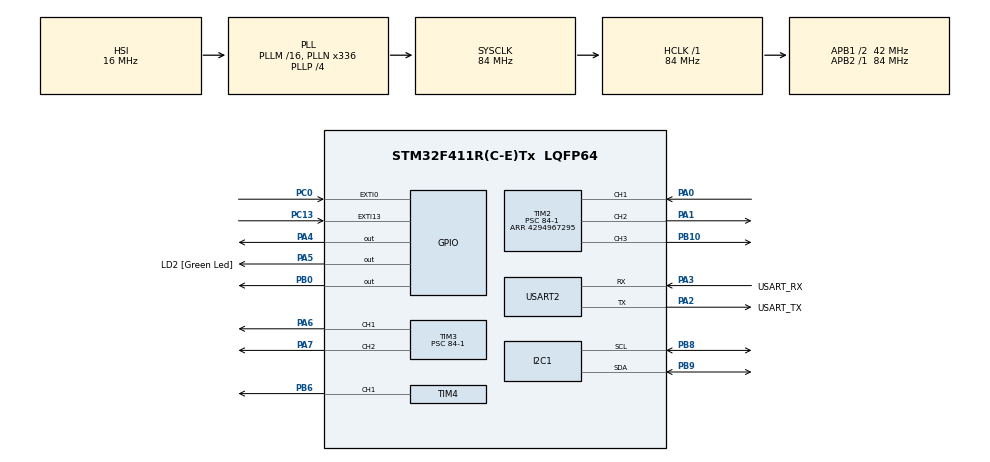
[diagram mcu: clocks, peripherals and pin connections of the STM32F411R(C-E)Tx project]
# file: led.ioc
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ADC1.Channel-0\#ChannelRegularConversion=ADC_CHANNEL_TEMPSENSOR
ADC1.ContinuousConvMode=ENABLE
ADC1.DMAContinuousRequests=ENABLE
ADC1.EOCSelection=ADC_EOC_SINGLE_CONV
ADC1.NbrOfConversion=1
ADC1.NbrOfConversionFlag=1
ADC1.Rank-0\#ChannelRegularConversion=1
ADC1.SamplingTime-0\#ChannelRegularConversion=ADC_SAMPLETIME_480CYCLES
ADC1.ScanConvMode=ENABLE
ADC1.master=1
Dma.ADC1.1.Direction=DMA_PERIPH_TO_MEMORY
Dma.ADC1.1.FIFOMode=DMA_FIFOMODE_DISABLE
Dma.ADC1.1.Instance=DMA2_Stream0
Dma.ADC1.1.MemDataAlignment=DMA_MDATAALIGN_WORD
Dma.ADC1.1.MemInc=DMA_MINC_ENABLE
Dma.ADC1.1.Mode=DMA_CIRCULAR
Dma.ADC1.1.PeriphDataAlignment=DMA_PDATAALIGN_WORD
Dma.ADC1.1.PeriphInc=DMA_PINC_DISABLE
Dma.ADC1.1.Priority=DMA_PRIORITY_LOW
Dma.Request0=USART2_RX
Dma.Request1=ADC1
Dma.USART2_RX.0.Direction=DMA_PERIPH_TO_MEMORY
Dma.USART2_RX.0.FIFOMode=DMA_FIFOMODE_DISABLE
Dma.USART2_RX.0.Instance=DMA1_Stream5
Dma.USART2_RX.0.MemDataAlignment=DMA_MDATAALIGN_BYTE
Dma.USART2_RX.0.MemInc=DMA_MINC_ENABLE
Dma.USART2_RX.0.Mode=DMA_CIRCULAR
Dma.USART2_RX.0.PeriphDataAlignment=DMA_PDATAALIGN_BYTE
Dma.USART2_RX.0.PeriphInc=DMA_PINC_DISABLE
Dma.USART2_RX.0.Priority=DMA_PRIORITY_LOW
FREERTOS.Tasks01=defaultTask,42,128,StartDefaultTask,As weak,NULL,Dynamic,NULL,NULL;myTask_LED,24,128,StartTaskLED,As weak,NULL,Dynamic,NULL,NULL;myTaskCLI,24,1024,StartTaskCLI,As weak,NULL,Dynamic,NULL,NULL;myTaskHCS04,24,128,StartTaskHCS04,As weak,NULL,Dynamic,NULL,NULL;myTaskDHT11,24,128,StartTaskDHT11,As weak,NULL,Dynamic,NULL,NULL;myTask01,41,128,StartTask01,As weak,NULL,Dynamic,NULL,NULL;myTask02,41,128,StartTask02,As weak,NULL,Dynamic,NULL,NULL
FREERTOS.configUSE_NEWLIB_REENTRANT=1
I2C1.I2C_Mode=I2C_Fast
Mcu.Family=STM32F4
Mcu.Name=STM32F411R(C-E)Tx
Mcu.Package=LQFP64
NVIC.ADC_IRQn=true\:5\:0\:false\:false\:true\:true\:true\:true\:true
NVIC.DMA1_Stream5_IRQn=true\:5\:0\:false\:false\:true\:true\:false\:true\:true
NVIC.DMA2_Stream0_IRQn=true\:5\:0\:false\:false\:true\:true\:false\:true\:true
NVIC.EXTI0_IRQn=true\:5\:0\:false\:false\:true\:true\:true\:true\:true
NVIC.EXTI15_10_IRQn=true\:5\:0\:false\:false\:true\:true\:true\:true\:true
NVIC.PriorityGroup=NVIC_PRIORITYGROUP_4
NVIC.RTC_Alarm_IRQn=true\:5\:0\:false\:false\:true\:true\:true\:true\:true
NVIC.TIM1_UP_TIM10_IRQn=true\:15\:0\:false\:false\:true\:false\:false\:true\:true
NVIC.TIM2_IRQn=true\:5\:0\:false\:false\:true\:true\:true\:true\:true
NVIC.TIM3_IRQn=true\:5\:0\:false\:false\:true\:true\:true\:true\:true
NVIC.TimeBase=TIM1_UP_TIM10_IRQn
NVIC.TimeBaseIP=TIM10
NVIC.USART2_IRQn=true\:5\:0\:false\:false\:true\:true\:true\:true\:true
PA0-WKUP.Signal=S_TIM2_CH1_ETR
PA1.Signal=S_TIM2_CH2
PA13.GPIO_Label=TMS
PA13.Mode=Serial_Wire
PA13.Signal=SYS_JTMS-SWDIO
PA14.GPIO_Label=TCK
PA14.Mode=Serial_Wire
PA14.Signal=SYS_JTCK-SWCLK
PA2.GPIO_Label=USART_TX
PA2.Mode=Asynchronous
PA2.Signal=USART2_TX
PA3.GPIO_Label=USART_RX
PA3.Mode=Asynchronous
PA3.Signal=USART2_RX
PA4.Signal=GPIO_Output
PA5.GPIO_Label=LD2 [Green Led]
PA5.Signal=GPIO_Output
PA6.Signal=S_TIM3_CH1
PA7.Signal=S_TIM3_CH2
PB0.Signal=GPIO_Output
PB10.Signal=S_TIM2_CH3
PB3.GPIO_Label=SWO
PB3.Signal=SYS_JTDO-SWO
PB6.Signal=S_TIM4_CH1
PB8.Mode=I2C
PB8.Signal=I2C1_SCL
PB9.Mode=I2C
PB9.Signal=I2C1_SDA
PC0.GPIO_ModeDefaultEXTI=GPIO_MODE_IT_FALLING
PC0.Signal=GPXTI0
PC13-ANTI_TAMP.Signal=GPXTI13
PC14-OSC32_IN.Mode=LSE-External-Oscillator
PC14-OSC32_IN.Signal=RCC_OSC32_IN
PC15-OSC32_OUT.Mode=LSE-External-Oscillator
PC15-OSC32_OUT.Signal=RCC_OSC32_OUT
PH0\ -\ OSC_IN.Mode=HSE-External-Clock-Source
PH0\ -\ OSC_IN.Signal=RCC_OSC_IN
PH1\ -\ OSC_OUT.Mode=HSE-External-Clock-Source
PH1\ -\ OSC_OUT.Signal=RCC_OSC_OUT
ProjectManager.HeapSize=0x200
ProjectManager.StackSize=0x400
ProjectManager.TargetToolchain=CMake
RCC.48MHZClocksFreq_Value=84000000
RCC.AHBFreq_Value=84000000
RCC.APB1CLKDivider=RCC_HCLK_DIV2
RCC.APB1Freq_Value=42000000
RCC.APB1TimFreq_Value=84000000
RCC.APB2Freq_Value=84000000
RCC.APB2TimFreq_Value=84000000
RCC.CortexFreq_Value=84000000
RCC.FLatency-AdvancedSettings=FLASH_LATENCY_2
RCC.HCLKFreq_Value=84000000
RCC.HSE_VALUE=8000000
RCC.HSI_VALUE=16000000
RCC.PLLN=336
RCC.PLLP=RCC_PLLP_DIV4
RCC.SYSCLKFreq_VALUE=84000000
RCC.SYSCLKSource=RCC_SYSCLKSOURCE_PLLCLK
RCC.VCOOutputFreq_Value=336000000
RTC.Alarm=RTC_ALARM_A
RTC.AlarmMaskDateWeekDay=RTC_ALARMMASK_DATEWEEKDAY
RTC.AlarmMaskHours=RTC_ALARMMASK_HOURS
RTC.AlarmMaskMinutes=RTC_ALARMMASK_MINUTES
RTC.Alarm_B=RTC_ALARM_B
RTC.Date=24
RTC.Hours=15
RTC.Minutes=47
RTC.Month=RTC_MONTH_AUGUST
RTC.Seconds_A=10
RTC.Year=26
SH.S_TIM2_CH1_ETR.0=TIM2_CH1,Input_Capture1_from_TI1
SH.S_TIM2_CH2.0=TIM2_CH2,PWM Generation2 CH2
SH.S_TIM2_CH3.0=TIM2_CH3,PWM Generation3 CH3
SH.S_TIM3_CH1.0=TIM3_CH1,PWM Generation1 CH1
SH.S_TIM3_CH2.0=TIM3_CH2,PWM Generation2 CH2
SH.S_TIM4_CH1.0=TIM4_CH1,PWM Generation1 CH1
TIM2.Channel-Input_Capture1_from_TI1=TIM_CHANNEL_1
TIM2.Channel-PWM\ Generation2\ CH2=TIM_CHANNEL_2
TIM2.Channel-PWM\ Generation3\ CH3=TIM_CHANNEL_3
TIM2.ICFilter_CH1=4
TIM2.ICPolarity_CH1=TIM_INPUTCHANNELPOLARITY_FALLING
TIM2.Period=4294967295
TIM2.Prescaler=84-1
TIM2.Pulse-PWM\ Generation2\ CH2=500-1
TIM2.Pulse-PWM\ Generation3\ CH3=500-1
TIM3.Channel-PWM\ Generation1\ CH1=TIM_CHANNEL_1
TIM3.Channel-PWM\ Generation2\ CH2=TIM_CHANNEL_2
TIM3.Period=1000-1
TIM3.Prescaler=84-1
TIM3.Pulse-PWM\ Generation1\ CH1=500-1
TIM3.Pulse-PWM\ Generation2\ CH2=500-1
TIM4.Channel-PWM\ Generation1\ CH1=TIM_CHANNEL_1
TIM4.Period=1000-1
TIM4.Prescaler=84-1
TIM4.Pulse-PWM\ Generation1\ CH1=500-1
USART2.VirtualMode=VM_ASYNC
VP_ADC1_TempSens_Input.Mode=IN-TempSens
VP_FREERTOS_VS_CMSIS_V2.Mode=CMSIS_V2
VP_RTC_VS_RTC_Activate.Mode=RTC_Enabled
VP_RTC_VS_RTC_Alarm_A_Intern.Mode=Alarm A
VP_RTC_VS_RTC_Alarm_B_Intern.Mode=Alarm B
VP_RTC_VS_RTC_Calendar.Mode=RTC_Calendar
VP_SYS_VS_tim10.Mode=TIM10
VP_TIM2_VS_ClockSourceINT.Mode=Internal
VP_TIM3_VS_ClockSourceINT.Mode=Internal
VP_TIM4_VS_ClockSourceINT.Mode=Internal
board=NUCLEO-F411RE

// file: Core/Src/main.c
/* USER CODE BEGIN Header */
/**
  ******************************************************************************
  * @file           : main.c
  * @brief          : Main program body
  ******************************************************************************
  * @attention
  *
  * Copyright (c) 2026 STMicroelectronics.
  * All rights reserved.
  *
  * This software is licensed under terms that can be found in the LICENSE file
  * in the root directory of this software component.
  * If no LICENSE file comes with this software, it is provided AS-IS.
  *
  ******************************************************************************
  */
/* USER CODE END Header */
#include "main.h"
#include "cmsis_os.h"
#include "adc.h"
#include "dma.h"
#include "i2c.h"
#include "rtc.h"
#include "tim.h"
#include "usart.h"
#include "gpio.h"

/* USER CODE BEGIN Includes */
#include "apMain.h"
/* USER CODE END Includes */

void SystemClock_Config(void);
void MX_FREERTOS_Init(void);

int main(void)
{

  /* MCU Configuration--------------------------------------------------------*/

  /* Reset of all peripherals, Initializes the Flash interface and the Systick. */
  HAL_Init();

  /* Configure the system clock */
  SystemClock_Config();

  /* Initialize all configured peripherals */
  MX_GPIO_Init();
  MX_DMA_Init();
  MX_USART2_UART_Init();
  MX_ADC1_Init();
  MX_I2C1_Init();
  MX_TIM2_Init();
  MX_TIM3_Init();
  MX_RTC_Init();
  MX_TIM4_Init();

  /* Init scheduler */
  osKernelInitialize();  /* Call init function for freertos objects (in cmsis_os2.c) */
  MX_FREERTOS_Init();

  /* Start scheduler */
  osKernelStart();

  /* We should never get here as control is now taken by the scheduler */

  /* Infinite loop */
  while (1)
  {

  }
}

void SystemClock_Config(void)
{
  RCC_OscInitTypeDef RCC_OscInitStruct = {0};
  RCC_ClkInitTypeDef RCC_ClkInitStruct = {0};

  /** Configure the main internal regulator output voltage
  */
  __HAL_RCC_PWR_CLK_ENABLE();
  __HAL_PWR_VOLTAGESCALING_CONFIG(PWR_REGULATOR_VOLTAGE_SCALE1);

  /** Initializes the RCC Oscillators according to the specified parameters
  * in the RCC_OscInitTypeDef structure.
  */
  RCC_OscInitStruct.OscillatorType = RCC_OSCILLATORTYPE_HSI|RCC_OSCILLATORTYPE_LSI;
  RCC_OscInitStruct.HSIState = RCC_HSI_ON;
  RCC_OscInitStruct.HSICalibrationValue = RCC_HSICALIBRATION_DEFAULT;
  RCC_OscInitStruct.LSIState = RCC_LSI_ON;
  RCC_OscInitStruct.PLL.PLLState = RCC_PLL_ON;
  RCC_OscInitStruct.PLL.PLLSource = RCC_PLLSOURCE_HSI;
  RCC_OscInitStruct.PLL.PLLM = 16;
  RCC_OscInitStruct.PLL.PLLN = 336;
  RCC_OscInitStruct.PLL.PLLP = RCC_PLLP_DIV4;
  RCC_OscInitStruct.PLL.PLLQ = 4;
  if (HAL_RCC_OscConfig(&RCC_OscInitStruct) != HAL_OK)
  {
    Error_Handler();
  }

  /** Initializes the CPU, AHB and APB buses clocks
  */
  RCC_ClkInitStruct.ClockType = RCC_CLOCKTYPE_HCLK|RCC_CLOCKTYPE_SYSCLK
                              |RCC_CLOCKTYPE_PCLK1|RCC_CLOCKTYPE_PCLK2;
  RCC_ClkInitStruct.SYSCLKSource = RCC_SYSCLKSOURCE_PLLCLK;
  RCC_ClkInitStruct.AHBCLKDivider = RCC_SYSCLK_DIV1;
  RCC_ClkInitStruct.APB1CLKDivider = RCC_HCLK_DIV2;
  RCC_ClkInitStruct.APB2CLKDivider = RCC_HCLK_DIV1;

  if (HAL_RCC_ClockConfig(&RCC_ClkInitStruct, FLASH_LATENCY_2) != HAL_OK)
  {
    Error_Handler();
  }
}

void HAL_TIM_PeriodElapsedCallback(TIM_HandleTypeDef *htim)
{
  if (htim->Instance == TIM10)
  {
    HAL_IncTick();
  }
}

void Error_Handler(void)
{
  __disable_irq();
  while (1)
  {
  }
}

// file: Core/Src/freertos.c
/* USER CODE BEGIN Header */
/**
  ******************************************************************************
  * File Name          : freertos.c
  * Description        : Code for freertos applications
  ******************************************************************************
  * @attention
  *
  * Copyright (c) 2026 STMicroelectronics.
  * All rights reserved.
  *
  * This software is licensed under terms that can be found in the LICENSE file
  * in the root directory of this software component.
  * If no LICENSE file comes with this software, it is provided AS-IS.
  *
  ******************************************************************************
  */
/* USER CODE END Header */

#include "FreeRTOS.h"
#include "task.h"
#include "main.h"
#include "cmsis_os.h"

/* Definitions for defaultTask */
osThreadId_t defaultTaskHandle;
const osThreadAttr_t defaultTask_attributes = {
  .name = "defaultTask",
  .stack_size = 128 * 4,
  .priority = (osPriority_t) osPriorityHigh2,
};
/* Definitions for myTask_LED */
osThreadId_t myTask_LEDHandle;
const osThreadAttr_t myTask_LED_attributes = {
  .name = "myTask_LED",
  .stack_size = 128 * 4,
  .priority = (osPriority_t) osPriorityNormal,
};
/* Definitions for myTaskCLI */
osThreadId_t myTaskCLIHandle;
const osThreadAttr_t myTaskCLI_attributes = {
  .name = "myTaskCLI",
  .stack_size = 1024 * 4,
  .priority = (osPriority_t) osPriorityNormal,
};
/* Definitions for myTaskHCS04 */
osThreadId_t myTaskHCS04Handle;
const osThreadAttr_t myTaskHCS04_attributes = {
  .name = "myTaskHCS04",
  .stack_size = 128 * 4,
  .priority = (osPriority_t) osPriorityNormal,
};
/* Definitions for myTaskDHT11 */
osThreadId_t myTaskDHT11Handle;
const osThreadAttr_t myTaskDHT11_attributes = {
  .name = "myTaskDHT11",
  .stack_size = 128 * 4,
  .priority = (osPriority_t) osPriorityNormal,
};
/* Definitions for myTask01 */
osThreadId_t myTask01Handle;
const osThreadAttr_t myTask01_attributes = {
  .name = "myTask01",
  .stack_size = 128 * 4,
  .priority = (osPriority_t) osPriorityHigh1,
};
/* Definitions for myTask02 */
osThreadId_t myTask02Handle;
const osThreadAttr_t myTask02_attributes = {
  .name = "myTask02",
  .stack_size = 128 * 4,
  .priority = (osPriority_t) osPriorityHigh1,
};

void StartDefaultTask(void *argument);
void StartTaskLED(void *argument);
void StartTaskCLI(void *argument);
void StartTaskHCS04(void *argument);
void StartTaskDHT11(void *argument);
void StartTask01(void *argument);
void StartTask02(void *argument);

void MX_FREERTOS_Init(void); /* (MISRA C 2004 rule 8.1) */

void MX_FREERTOS_Init(void) {

  /* Create the thread(s) */
  /* creation of defaultTask */
  defaultTaskHandle = osThreadNew(StartDefaultTask, NULL, &defaultTask_attributes);

  /* creation of myTask_LED */
  myTask_LEDHandle = osThreadNew(StartTaskLED, NULL, &myTask_LED_attributes);

  /* creation of myTaskCLI */
  myTaskCLIHandle = osThreadNew(StartTaskCLI, NULL, &myTaskCLI_attributes);

  /* creation of myTaskHCS04 */
  myTaskHCS04Handle = osThreadNew(StartTaskHCS04, NULL, &myTaskHCS04_attributes);

  /* creation of myTaskDHT11 */
  myTaskDHT11Handle = osThreadNew(StartTaskDHT11, NULL, &myTaskDHT11_attributes);

  /* creation of myTask01 */
  myTask01Handle = osThreadNew(StartTask01, NULL, &myTask01_attributes);

  /* creation of myTask02 */
  myTask02Handle = osThreadNew(StartTask02, NULL, &myTask02_attributes);

}

__weak void StartDefaultTask(void *argument)
{
  for(;;)
  {
    osDelay(1);
  }
}

__weak void StartTaskLED(void *argument)
{
  for(;;)
  {
    osDelay(1);
  }
}

__weak void StartTaskCLI(void *argument)
{
  for(;;)
  {
    osDelay(1);
  }
}

__weak void StartTaskHCS04(void *argument)
{
  for(;;)
  {
    osDelay(1);
  }
}

__weak void StartTaskDHT11(void *argument)
{
  for(;;)
  {
    osDelay(1);
  }
}

__weak void StartTask01(void *argument)
{
  for(;;)
  {
    osDelay(1);
  }
}

__weak void StartTask02(void *argument)
{
  for(;;)
  {
    osDelay(1);
  }
}
